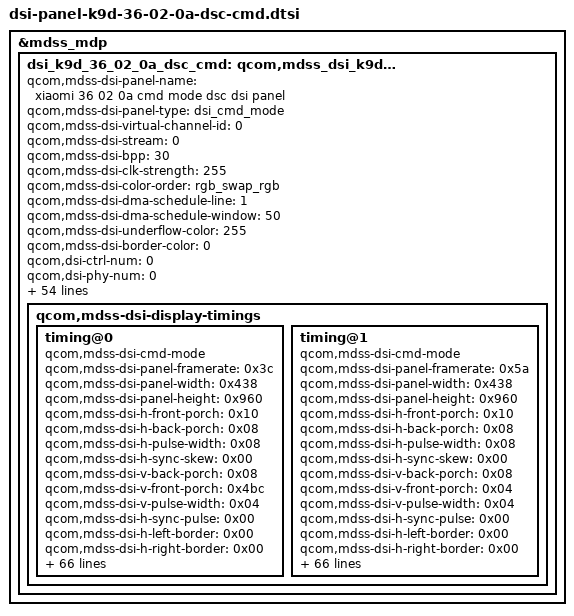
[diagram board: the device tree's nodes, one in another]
&mdss_mdp {
	dsi_k9d_36_02_0a_dsc_cmd: qcom,mdss_dsi_k9d_36_02_0a_dsc_cmd {
		qcom,mdss-dsi-panel-name = "xiaomi 36 02 0a cmd mode dsc dsi panel";
		qcom,mdss-dsi-panel-type = "dsi_cmd_mode";
		qcom,mdss-dsi-virtual-channel-id = <0>;
		qcom,mdss-dsi-stream = <0>;
		qcom,mdss-dsi-bpp = <30>;
		qcom,mdss-dsi-clk-strength = <255>;
		qcom,mdss-dsi-color-order = "rgb_swap_rgb";
		qcom,mdss-dsi-dma-schedule-line = <1>;
		qcom,mdss-dsi-dma-schedule-window = <50>;
		qcom,mdss-dsi-underflow-color = <255>;
		qcom,mdss-dsi-border-color = <0>;

		qcom,dsi-ctrl-num = <0>;
		qcom,dsi-phy-num = <0>;

		qcom,mdss-dsi-traffic-mode = "burst_mode";
		qcom,mdss-dsi-lane-map = "lane_map_0123";
		qcom,mdss-dsi-bllp-eof-power-mode;
		qcom,mdss-dsi-bllp-power-mode;
		qcom,mdss-dsi-lane-0-state;
		qcom,mdss-dsi-lane-1-state;
		qcom,mdss-dsi-lane-2-state;
		qcom,mdss-dsi-lane-3-state;
		qcom,mdss-dsi-dma-trigger = "trigger_sw";
		qcom,mdss-dsi-mdp-trigger = "none";
		qcom,mdss-dsi-reset-sequence =  <1 11>, <0 1>, <1 11>;
		qcom,mdss-factory-brightness-max-level = <2047>;
		qcom,mdss-pan-physical-height-dimension = <1517>;
		qcom,mdss-pan-physical-width-dimension = <683>;
		qcom,mdss-dsi-te-pin-select = <1>;
		qcom,mdss-dsi-wr-mem-start = <0x2c>;
		qcom,mdss-dsi-wr-mem-continue = <0x3c>;
		qcom,mdss-dsi-te-dcs-command = <1>;
		qcom,mdss-dsi-te-check-enable;
		qcom,mdss-dsi-te-using-te-pin;
		qcom,mdss-dsi-tx-eot-append;
		qcom,mdss-dsi-lp11-init;

		qcom,mdss-dsi-bl-inverted-dbv;
		qcom,bl-update-flag = "delay_until_first_frame";
		qcom,mdss-dsi-panel-blackness-level = <3230>;
		qcom,mdss-dsi-panel-hdr-color-primaries = <0x38a4 0x3c8c 0x7d00 0x4268 0x3c8c 0x7530 0x1f40 0xbb8>;
		qcom,mdss-dsi-panel-hdr-enabled;

		qcom,mdss-dsi-display-timings {
			timing@0{
				qcom,mdss-dsi-cmd-mode;
				qcom,mdss-dsi-panel-framerate = <60>;
				qcom,mdss-dsi-panel-width = <1080>;
				qcom,mdss-dsi-panel-height = <2400>;
				qcom,mdss-dsi-h-front-porch = <16>;
				qcom,mdss-dsi-h-back-porch = <8>;
				qcom,mdss-dsi-h-pulse-width = <8>;
				qcom,mdss-dsi-h-sync-skew = <0>;
				qcom,mdss-dsi-v-back-porch = <8>;
				qcom,mdss-dsi-v-front-porch = <1212>;
				qcom,mdss-dsi-v-pulse-width = <4>;
				qcom,mdss-dsi-h-sync-pulse = <0>;
				qcom,mdss-dsi-h-left-border = <0>;
				qcom,mdss-dsi-h-right-border = <0>;
				qcom,mdss-dsi-v-top-border = <0>;
				qcom,mdss-dsi-v-bottom-border = <0>;
				qcom,mdss-dsi-panel-clockrate = <682000000>;
				qcom,mdss-dsi-panel-jitter = <0x5 0x1>;
				qcom,mdss-mdp-transfer-time-us = <9500>;
				qcom,mdss-dsi-on-command = [
					/* Command Mode */
					39 00 00 00 00 00 06 F0 55 AA 52 08 00
					39 01 00 00 00 00 03 C0 52 F3
					/* ESD/MIPI Error Flag, Low when Error Happen */
					39 00 00 00 00 00 06 F0 55 AA 52 08 00
					39 00 00 00 00 00 05 BE 0E 0B 14 13
					15 00 00 00 00 00 02 6F 05
					15 01 00 00 00 00 02 BE 8A
					/* Round Corner OFF */
					39 00 00 00 00 00 06 F0 55 AA 52 08 07
					39 01 00 00 00 00 03 C0 00 02
					/* VESA ON */
					39 00 00 00 00 00 06 F0 55 AA 52 08 01	// Set page 1
					39 00 00 00 00 00 04 D1 07 00 04
					39 00 00 00 00 00 05 B3 12 12 22 22
					39 00 00 00 00 00 05 B4 12 12 22 22
					15 01 00 00 00 00 02 90 01
					/* Choose VESA Edition */
					39 00 00 00 00 00 13 91
						AB 28 00 0C C2 00 03 1C 01 7E
						00 0F 08 BB 04 3D 10 F0	// DSC Setting
					15 00 00 00 00 00 02 03 01
					39 00 00 00 00 00 05 51 00 00 00 00	// Normal Mode
					15 00 00 00 00 00 02 53 20
					15 00 00 00 00 00 02 35 00	// TE ON
					39 00 00 00 00 00 05 2A 00 00 04 37
					39 00 00 00 00 00 05 2B 00 00 09 5F
					15 01 00 00 00 00 02 2F 02	// 60Hz
					/* OSC=109.2MHz */
					39 00 00 00 00 00 05 FF AA 55 A5 81
					15 00 00 00 00 00 02 6F 0F
					39 01 00 00 00 00 03 FD 01 5A
					/* Demura Gain */
					39 00 00 00 00 00 05 FF AA 55 A5 80
					39 00 00 00 00 00 04 C0 76 F3 C1
					39 00 00 00 00 00 06 F0 55 AA 52 08 04
					15 00 00 00 00 00 02 C2 14
					15 00 00 00 00 00 02 B1 02
					15 00 00 00 00 00 02 B2 40
					15 00 00 00 00 00 02 6F 04
					39 00 00 00 00 00 04 B2 09 E4 00
					15 00 00 00 00 00 02 6F 0A
					39 00 00 00 00 00 04 B2 09 E3 40
					15 00 00 00 00 00 02 CB A4
					39 01 00 00 00 00 05 D0 00 80 00 20
					/* AOD Demura */
					15 00 00 00 00 00 02 B0 01
					39 00 00 00 00 00 06 F0 55 AA 52 08 00
					15 00 00 00 00 00 02 6F 01
					15 01 00 00 00 00 02 C0 B3
					/* AOD Demura End */
					39 00 00 00 00 00 06 F0 55 AA 52 08 04
					15 00 00 00 00 00 02 6F 04
					15 01 00 00 00 00 02 D0 01
					39 00 00 00 00 00 06 F0 55 AA 52 08 00
					15 00 00 00 00 00 02 6F 08
					15 00 00 00 00 00 02 C0 55
					15 01 00 00 00 00 02 8B 10
					39 00 00 00 00 00 06 F0 55 AA 52 08 04
					15 00 00 00 00 00 02 6F 01
					39 01 00 00 00 00 10 CB
						10 20 30 40 80 00 08 00 F6 01
						C2 04 CC 07 FF
					/* 90Hz Gain */
					39 01 00 00 00 00 4C D2
						E0 50 36 2C 27 B0 56 48 34 2E
						A0 60 51 40 32 90 69 59 47 40
						90 73 60 4C 40 E0 50 36 2C 27
						B0 56 48 34 2E A0 60 51 40 32
						90 69 59 47 40 90 73 60 4C 40
						E0 50 36 2C 27 B0 56 48 34 2E
						A0 60 51 40 32 90 69 59 47 40
						90 73 60 4C 40
					/* 60Hz Gain */
					39 01 00 00 00 00 4C D4
						C0 A0 90 90 90 36 39 40 50 60
						25 2C 38 46 5A 24 2B 35 44 48
						13 2A 32 42 42 C0 A0 90 90 90
						36 39 40 50 60 25 2C 38 46 5A
						24 2B 35 44 48 13 2A 32 42 42
						C0 A0 90 90 90 36 39 40 50 60
						25 2C 38 46 5A 24 2B 35 44 48
						13 2A 32 42 42
					/* Demura DC */
					39 01 00 00 00 00 4C D9
						40 40 40 40 40 40 40 40 40 40
						40 40 40 40 40 40 40 40 40 40
						40 40 40 40 40 40 40 40 40 40
						40 40 40 40 40 40 40 40 40 40
						40 40 40 40 40 40 40 40 40 40
						40 40 40 40 40 40 40 40 40 40
						40 40 40 40 40 40 40 40 40 40
						40 40 40 40 40
					/* FCON code */
					39 00 00 00 00 00 06 F0 55 AA 52 08 00
					/* FCON = 1 (90hz) */
					39 00 00 00 00 00 09 BA 01 E9 00 10 00 30 00 01
					/* FCON = 2 (60hz) */
					15 00 00 00 00 00 02 6F 08
					39 00 00 00 00 00 09 BA 01 E9 00 10 04 D0 00 01	// PWM 60&90Hz
					/* FCON = 3 (DC=60hz) */
					15 00 00 00 00 00 02 6F 10
					39 00 00 00 00 00 09 BA 01 E9 00 10 04 D0 00 01
					39 00 00 00 00 00 03 B2 50 63
					15 00 00 00 00 00 02 6F 05
					39 00 00 00 00 00 03 B2 30 30	// Dimming speed: 48 DBV/Frame
					15 00 00 00 00 00 02 6F 0F
					39 00 00 00 00 00 03 B2 20 50
					/* EM_DT_0_HFR1 ~EM_DT_0_HFR18 (60hz) */
					15 00 00 00 00 00 02 6F 2C
					39 00 00 00 00 00 27 B3
						0E 40 0D F5 0C D2 0C D2 0C 3C
						0C 3C 0A 51 0A 51 06 44 06 44
						00 6A 00 6A 00 6A 00 6A 00 6A
						00 6A 00 6A 00 6A 00 6A
					/* EM_DT_0~EM_DT_18 (90hz) */
					39 01 00 00 00 00 27 B4
						09 A0 09 6E 08 A9 08 A9 08 44
						08 44 06 F8 06 F8 04 3C 04 3C
						00 48 00 48 00 48 00 48 00 48
						00 48 00 48 00 48 00 48
					/* Sleep Out */
					05 01 00 00 78 00 02 11 00
					/* Display On */
					05 01 00 00 10 00 02 29 00];
				qcom,mdss-dsi-off-command = [
					05 01 00 00 00 00 02 28 00
					05 01 00 00 78 00 02 10 00];
				qcom,mdss-dsi-on-command-state = "dsi_lp_mode";
				qcom,mdss-dsi-off-command-state = "dsi_lp_mode";

				qcom,mdss-dsi-timing-switch-command = [
					15 01 00 00 00 00 02 2F 02];
				qcom,mdss-dsi-timing-switch-command-state = "dsi_lp_mode";

				qcom,mdss-dsi-nolp-command = [
					15 00 00 00 00 00 02 65 00
					05 00 00 00 00 00 01 38
					05 00 00 00 00 00 01 2C
					15 01 00 00 00 00 02 2F 02];
				qcom,mdss-dsi-nolp-command-state = "dsi_lp_mode";

				qcom,compression-mode = "dsc";
				qcom,mdss-dsc-version = <0x11>;
				qcom,mdss-dsc-scr-version = <0x0>;
				qcom,mdss-dsc-slice-height = <12>;
				qcom,mdss-dsc-slice-width = <1080>;
				qcom,mdss-dsc-slice-per-pkt = <1>;
				qcom,mdss-dsc-bit-per-component = <10>;
				qcom,mdss-dsc-bit-per-pixel = <8>;
				qcom,mdss-dsc-block-prediction-enable;
			};

			timing@1{
				qcom,mdss-dsi-cmd-mode;
				qcom,mdss-dsi-panel-framerate = <90>;
				qcom,mdss-dsi-panel-width = <1080>;
				qcom,mdss-dsi-panel-height = <2400>;
				qcom,mdss-dsi-h-front-porch = <16>;
				qcom,mdss-dsi-h-back-porch = <8>;
				qcom,mdss-dsi-h-pulse-width = <8>;
				qcom,mdss-dsi-h-sync-skew = <0>;
				qcom,mdss-dsi-v-back-porch = <8>;
				qcom,mdss-dsi-v-front-porch = <4>;
				qcom,mdss-dsi-v-pulse-width = <4>;
				qcom,mdss-dsi-h-sync-pulse = <0>;
				qcom,mdss-dsi-h-left-border = <0>;
				qcom,mdss-dsi-h-right-border = <0>;
				qcom,mdss-dsi-v-top-border = <0>;
				qcom,mdss-dsi-v-bottom-border = <0>;
				qcom,mdss-dsi-panel-clockrate = <682000000>;
				qcom,mdss-dsi-panel-jitter = <0x5 0x1>;
				qcom,mdss-mdp-transfer-time-us = <9500>;
				qcom,mdss-dsi-on-command = [
					/* Command Mode */
					39 00 00 00 00 00 06 F0 55 AA 52 08 00
					39 01 00 00 00 00 03 C0 52 F3
					/* ESD/MIPI Error Flag, Low when Error Happen */
					39 00 00 00 00 00 06 F0 55 AA 52 08 00
					39 00 00 00 00 00 05 BE 0E 0B 14 13
					15 00 00 00 00 00 02 6F 05
					15 01 00 00 00 00 02 BE 8A
					/* Round Corner OFF */
					39 00 00 00 00 00 06 F0 55 AA 52 08 07
					39 01 00 00 00 00 03 C0 00 02
					/* VESA ON */
					39 00 00 00 00 00 06 F0 55 AA 52 08 01	// Set page 1
					39 00 00 00 00 00 04 D1 07 00 04
					39 00 00 00 00 00 05 B3 12 12 22 22
					39 00 00 00 00 00 05 B4 12 12 22 22
					15 01 00 00 00 00 02 90 01
					/* Choose VESA Edition */
					39 00 00 00 00 00 13 91
						AB 28 00 0C C2 00 03 1C 01 7E
						00 0F 08 BB 04 3D 10 F0	// DSC Setting
					15 00 00 00 00 00 02 03 01
					39 00 00 00 00 00 05 51 00 00 00 00	// Normal Mode
					15 00 00 00 00 00 02 53 20
					15 00 00 00 00 00 02 35 00	// TE ON
					39 00 00 00 00 00 05 2A 00 00 04 37
					39 00 00 00 00 00 05 2B 00 00 09 5F
					15 01 00 00 00 00 02 2F 01	// 90Hz
					/* OSC=109.2MHz */
					39 00 00 00 00 00 05 FF AA 55 A5 81
					15 00 00 00 00 00 02 6F 0F
					39 01 00 00 00 00 03 FD 01 5A
					/* Demura Gain */
					39 00 00 00 00 00 05 FF AA 55 A5 80
					39 01 00 00 00 00 04 C0 76 F3 C1
					39 00 00 00 00 00 06 F0 55 AA 52 08 04
					15 00 00 00 00 00 02 C2 14
					15 00 00 00 00 00 02 B1 02
					15 00 00 00 00 00 02 B2 40
					15 00 00 00 00 00 02 6F 04
					39 00 00 00 00 00 04 B2 09 E4 00
					15 00 00 00 00 00 02 6F 0A
					39 00 00 00 00 00 04 B2 09 E3 40
					15 00 00 00 00 00 02 CB A4
					39 01 00 00 00 00 05 D0 00 80 00 20
					/* AOD Demura */
					15 00 00 00 00 00 02 B0 01
					39 00 00 00 00 00 06 F0 55 AA 52 08 00
					15 00 00 00 00 00 02 6F 01
					15 01 00 00 00 00 02 C0 B3
					/* AOD Demura End */
					39 00 00 00 00 00 06 F0 55 AA 52 08 04
					15 00 00 00 00 00 02 6F 04
					15 01 00 00 00 00 02 D0 01
					39 00 00 00 00 00 06 F0 55 AA 52 08 00
					15 00 00 00 00 00 02 6F 08
					15 00 00 00 00 00 02 C0 55
					15 01 00 00 00 00 02 8B 10
					39 00 00 00 00 00 06 F0 55 AA 52 08 04
					15 00 00 00 00 00 02 6F 01
					39 01 00 00 00 00 10 CB
						10 20 30 40 80 00 08 00 F6 01
						C2 04 CC 07 FF
					/* 90Hz Gain */
					39 01 00 00 00 00 4C D2
						E0 50 36 2C 27 B0 56 48 34 2E
						A0 60 51 40 32 90 69 59 47 40
						90 73 60 4C 40 E0 50 36 2C 27
						B0 56 48 34 2E A0 60 51 40 32
						90 69 59 47 40 90 73 60 4C 40
						E0 50 36 2C 27 B0 56 48 34 2E
						A0 60 51 40 32 90 69 59 47 40
						90 73 60 4C 40
					/* 60Hz Gain */
					39 01 00 00 00 00 4C D4
						C0 A0 90 90 90 36 39 40 50 60
						25 2C 38 46 5A 24 2B 35 44 48
						13 2A 32 42 42 C0 A0 90 90 90
						36 39 40 50 60 25 2C 38 46 5A
						24 2B 35 44 48 13 2A 32 42 42
						C0 A0 90 90 90 36 39 40 50 60
						25 2C 38 46 5A 24 2B 35 44 48
						13 2A 32 42 42
					/* Demura DC */
					39 01 00 00 00 00 4C D9
						40 40 40 40 40 40 40 40 40 40
						40 40 40 40 40 40 40 40 40 40
						40 40 40 40 40 40 40 40 40 40
						40 40 40 40 40 40 40 40 40 40
						40 40 40 40 40 40 40 40 40 40
						40 40 40 40 40 40 40 40 40 40
						40 40 40 40 40 40 40 40 40 40
						40 40 40 40 40
					/* FCON code */
					39 00 00 00 00 00 06 F0 55 AA 52 08 00
					/* FCON = 1 (90hz) */
					39 00 00 00 00 00 09 BA 01 E9 00 10 00 30 00 01
					/* FCON = 2 (60hz) */
					15 00 00 00 00 00 02 6F 08
					39 00 00 00 00 00 09 BA 01 E9 00 10 04 D0 00 01	// PWM 60&90Hz
					/* FCON = 3 (DC=60hz) */
					15 00 00 00 00 00 02 6F 10
					39 00 00 00 00 00 09 BA 01 E9 00 10 04 D0 00 01
					39 00 00 00 00 00 03 B2 50 63
					15 00 00 00 00 00 02 6F 05
					39 00 00 00 00 00 03 B2 20 20	// Dimming speed: 32 DBV/Frame
					15 00 00 00 00 00 02 6F 0F
					39 00 00 00 00 00 03 B2 20 50
					/* EM_DT_0_HFR1 ~EM_DT_0_HFR18 (60hz) */
					15 00 00 00 00 00 02 6F 2C
					39 00 00 00 00 00 27 B3
						0E 40 0D F5 0C D2 0C D2 0C 3C
						0C 3C 0A 51 0A 51 06 44 06 44
						00 6A 00 6A 00 6A 00 6A 00 6A
						00 6A 00 6A 00 6A 00 6A
					/* EM_DT_0~EM_DT_18 (90hz) */
					39 01 00 00 00 00 27 B4
						09 A0 09 6E 08 A9 08 A9 08 44
						08 44 06 F8 06 F8 04 3C 04 3C
						00 48 00 48 00 48 00 48 00 48
						00 48 00 48 00 48 00 48
					/* Sleep Out */
					05 01 00 00 8C 00 02 11 00
					/* Display On */
					05 01 00 00 10 00 02 29 00];
				qcom,mdss-dsi-off-command = [
					05 01 00 00 00 00 02 28 00
					05 01 00 00 78 00 02 10 00];
				qcom,mdss-dsi-on-command-state = "dsi_lp_mode";
				qcom,mdss-dsi-off-command-state = "dsi_lp_mode";

				qcom,mdss-dsi-timing-switch-command = [
					15 01 00 00 00 00 02 2F 01];
				qcom,mdss-dsi-timing-switch-command-state = "dsi_lp_mode";

				qcom,mdss-dsi-nolp-command = [
					15 00 00 00 00 00 02 65 00
					05 00 00 00 00 00 01 38
					05 00 00 00 00 00 01 2C
					15 01 00 00 00 00 02 2F 01];
				qcom,mdss-dsi-nolp-command-state = "dsi_lp_mode";

				qcom,compression-mode = "dsc";
				qcom,mdss-dsc-version = <0x11>;
				qcom,mdss-dsc-scr-version = <0x0>;
				qcom,mdss-dsc-slice-height = <12>;
				qcom,mdss-dsc-slice-width = <1080>;
				qcom,mdss-dsc-slice-per-pkt = <1>;
				qcom,mdss-dsc-bit-per-component = <10>;
				qcom,mdss-dsc-bit-per-pixel = <8>;
				qcom,mdss-dsc-block-prediction-enable;
			};
		};
	};
};

&dsi_k9d_36_02_0a_dsc_cmd {
	mi,panel-id = <0x4b3944 0x360200>;
	mi,fp-display-on-optimize-flag;
	mi,hbm-51-ctl-flag;
	mi,hbm-off-51-index = <1>;
	mi,hbm-on-51-index = <1>;
	mi,max-brightness-clone = <4095>;
	mi,hbm-bl-min-level = <1>;
	mi,hbm-bl-max-level = <2047>;
	mi,panel-on-dimming-delay = <120>;
	mi,thermal-dimming-flag;
	mi,timming-switch-wait-for-te-flag;

	/* IRQF_ONESHOT | IRQF_TRIGGER_FALLING */
	mi,esd-err-irq-gpio = <&tlmm 3 0x2002>;

	qcom,esd-check-enabled;
	qcom,esd-aod-check-enabled;
	qcom,mdss-dsi-panel-status-check-mode = "reg_read";
	qcom,mdss-dsi-panel-status-offset-command = [
		39 01 00 00 00 00 05 FF AA 55 A5 81
		15 01 00 00 00 00 02 6F 0F];
	qcom,mdss-dsi-panel-status-command = [06 01 00 00 00 00 01 FA];
	qcom,mdss-dsi-panel-status-command-state = "dsi_lp_mode";
	qcom,mdss-dsi-panel-status-offset-command-state = "dsi_lp_mode";
	qcom,mdss-dsi-panel-status-value = <0x00>;
	qcom,mdss-dsi-panel-status-read-length = <1>;

	qcom,mdss-dsi-display-timings {
		timing@0 {
			mi,mdss-dsc-panel-id = <0x4b3944 0x360200>;
			mi,mdss-dsi-dimmingoff-command = [15 01 00 00 00 00 02 53 20];
			mi,mdss-dsi-dimmingoff-command-state = "dsi_hs_mode";
			mi,mdss-dsi-dimmingon-command = [15 01 00 00 00 00 02 53 28];
			mi,mdss-dsi-dimmingon-command-state = "dsi_hs_mode";
			mi,mdss-dsi-doze-hbm-command = [15 01 00 00 00 00 02 2f 01 39 01 00 00 00 00 05 51 00 00 03 ff 05 01 00 00 14 00 01 39 15 01 00 00 00 00 02 65 01];
			mi,mdss-dsi-doze-hbm-command-state = "dsi_lp_mode";
			mi,mdss-dsi-doze-lbm-command = [15 01 00 00 00 00 02 2f 01 39 01 00 00 00 00 05 51 00 00 01 ff 05 01 00 00 14 00 01 39 15 01 00 00 00 00 02 65 01];
			mi,mdss-dsi-doze-lbm-command-state = "dsi_lp_mode";
			mi,mdss-dsi-flat-mode-off-command = [39 01 00 00 00 00 06 f0 55 aa 52 08 08 15 01 00 00 00 00 02 b9 00];
			mi,mdss-dsi-flat-mode-off-command-state = "dsi_lp_mode";
			mi,mdss-dsi-flat-mode-on-command = [39 01 00 00 00 00 06 f0 55 aa 52 08 08 15 01 00 00 00 00 02 b9 01];
			mi,mdss-dsi-flat-mode-on-command-state = "dsi_lp_mode";
			mi,mdss-dsi-hbm-off-command = [15 01 00 00 00 00 02 53 28 39 01 00 00 00 00 05 51 07 ff 00 00];
			mi,mdss-dsi-hbm-off-command-state = "dsi_lp_mode";
			mi,mdss-dsi-hbm-on-command = [15 01 00 00 00 00 02 53 28 39 01 00 00 00 00 05 51 0f ff 00 00];
			mi,mdss-dsi-hbm-on-command-state = "dsi_lp_mode";
			mi,mdss-dsi-pre-doze-to-off-command = [39 00 00 00 00 00 06 f0 55 aa 52 08 01 39 01 00 00 00 00 02 ce 0c];
			mi,mdss-dsi-pre-doze-to-off-command-state = "dsi_lp_mode";
			qcom,compression-mode = "dsc";
			qcom,default-topology-index = <0x00>;
			qcom,display-topology = <0x01 0x01 0x01>;
			qcom,mdss-dsc-bit-per-component = <0x0a>;
			qcom,mdss-dsc-bit-per-pixel = <0x08>;
			qcom,mdss-dsc-block-prediction-enable;
			qcom,mdss-dsc-scr-version = <0x00>;
			qcom,mdss-dsc-slice-height = <0x0c>;
			qcom,mdss-dsc-slice-per-pkt = <0x01>;
			qcom,mdss-dsc-slice-width = <0x438>;
			qcom,mdss-dsc-version = <0x11>;
			qcom,mdss-dsi-cmd-mode;
			qcom,mdss-dsi-h-back-porch = <0x08>;
			qcom,mdss-dsi-h-front-porch = <0x10>;
			qcom,mdss-dsi-h-left-border = <0x00>;
			qcom,mdss-dsi-h-pulse-width = <0x08>;
			qcom,mdss-dsi-h-right-border = <0x00>;
			qcom,mdss-dsi-h-sync-pulse = <0x00>;
			qcom,mdss-dsi-h-sync-skew = <0x00>;
			qcom,mdss-dsi-nolp-command = [15 01 00 00 00 00 02 65 00 05 01 00 00 07 00 01 38 39 01 00 00 00 00 06 f0 55 aa 52 08 01 39 01 00 00 1b 00 05 ba 10 1a 10 1a 39 01 00 00 00 00 05 ba 10 10 10 10 15 01 00 00 00 00 02 2f 02];
			qcom,mdss-dsi-nolp-command-state = "dsi_lp_mode";
			qcom,mdss-dsi-off-command = [05 01 00 00 14 00 02 28 00 05 01 00 00 50 00 02 10 00];
			qcom,mdss-dsi-off-command-state = "dsi_lp_mode";
			qcom,mdss-dsi-on-command = [39 01 00 00 00 00 06 f0 55 aa 52 08 00 39 00 00 00 00 00 09 ba 01 e6 00 10 00 30 00 01 15 00 00 00 00 00 02 b2 58 15 00 00 00 00 00 02 6f 02 39 00 00 00 00 00 03 b2 0c 0c 39 00 00 00 00 00 05 be 0e 0b 14 13 15 00 00 00 00 00 02 6f 05 15 00 00 00 00 00 02 be 8a 15 00 00 00 00 00 02 c0 66 15 00 00 00 00 00 02 6f 08 15 01 00 00 00 00 02 b5 32 39 00 00 00 00 00 06 f0 55 aa 52 08 07 39 01 00 00 00 00 03 c0 00 02 39 01 00 00 00 00 06 f0 55 aa 52 08 01 39 00 00 00 00 00 02 6f 01 39 00 00 00 00 00 04 d2 00 00 11 39 00 00 00 00 00 02 6f 06 39 00 00 00 00 00 02 d2 05 39 00 00 00 00 00 02 6f 0f 39 00 00 00 00 00 02 d2 00 39 00 00 00 00 00 02 6f 09 39 00 00 00 00 00 03 d2 00 00 39 00 00 00 00 00 02 ce 00 39 00 00 00 00 00 05 ff aa 55 a5 80 39 00 00 00 00 00 02 6f 61 39 00 00 00 00 00 02 f3 80 39 00 00 00 00 00 06 f0 55 aa 52 08 00 39 00 00 00 00 00 02 c0 46 39 00 00 00 00 00 03 be 0e 0b 39 00 00 00 00 00 02 6f 05 39 00 00 00 00 00 02 be 88 39 00 00 00 00 00 02 6f 08 39 00 00 00 00 00 02 b5 32 39 00 00 00 00 00 02 6f 0b 39 00 00 00 00 00 04 b5 33 23 2b 39 00 00 00 00 00 06 f0 55 aa 52 08 01 39 00 00 00 00 00 04 d1 07 00 04 39 00 00 00 00 00 05 3b 00 10 00 30 39 00 00 00 00 00 02 d9 c8 15 01 00 00 00 00 02 90 01 39 00 00 00 00 00 13 91 ab 28 00 0c c2 00 03 1c 01 7e 00 0f 08 bb 04 3d 10 f0 15 00 00 00 00 00 02 03 01 39 00 00 00 00 00 05 51 00 00 00 00 15 00 00 00 00 00 02 53 20 15 00 00 00 00 00 02 35 00 39 00 00 00 00 00 05 2a 00 00 04 37 39 00 00 00 00 00 05 2b 00 00 09 5f 15 01 00 00 00 00 02 2f 02 39 00 00 00 00 00 05 ff aa 55 a5 81 15 00 00 00 00 00 02 6f 0f 39 00 00 00 00 00 03 fd 01 5a 15 00 00 00 00 00 02 6f 04 15 00 00 00 00 00 02 fd 5f 15 00 00 00 00 00 02 6f 1a 15 00 00 00 00 00 02 fd 5f 05 01 00 00 00 00 01 2c 39 00 00 00 00 00 06 f0 55 aa 52 08 00 39 00 00 00 00 00 05 ca 12 00 92 02 15 00 00 00 00 00 02 6f 02 39 00 00 00 00 00 03 ec 80 10 39 00 00 00 00 00 06 f0 55 aa 52 08 01 39 00 00 00 00 00 03 cd 05 31 15 00 00 00 00 00 02 6f 10 15 00 00 00 00 00 02 d8 0c 39 00 00 00 00 00 06 f0 55 aa 52 08 05 39 00 00 00 00 00 03 b3 86 80 39 00 00 00 00 00 03 b5 85 81 39 00 00 00 00 00 05 b7 85 00 00 81 39 00 00 00 00 00 05 b8 05 00 00 81 39 00 00 00 00 00 03 ec 0d 11 15 00 00 00 00 00 02 6f 02 39 01 00 00 00 00 13 ec 00 00 00 00 00 00 00 00 00 00 00 00 00 00 00 00 00 00 39 00 00 00 00 00 06 f0 55 aa 52 08 01 15 00 00 00 00 00 02 6f 01 39 00 00 00 00 00 04 d2 01 28 33 15 00 00 00 00 00 02 6f 06 15 00 00 00 00 00 02 d2 00 15 00 00 00 00 00 02 6f 0f 15 00 00 00 00 00 02 d2 00 39 00 00 00 00 00 08 c3 94 01 97 d0 22 02 00 15 00 00 00 00 00 02 6f 09 15 01 00 00 00 00 02 d2 00 05 01 00 00 32 00 02 11 00 05 01 00 00 10 00 02 29 00];
			qcom,mdss-dsi-on-command-state = "dsi_lp_mode";
			qcom,mdss-dsi-panel-clockrate = <0x28a67e80>;
			qcom,mdss-dsi-panel-framerate = <0x3c>;
			qcom,mdss-dsi-panel-height = <0x960>;
			qcom,mdss-dsi-panel-jitter = <0x05 0x01>;
			qcom,mdss-dsi-panel-phy-timings = [00 18 06 06 21 20 06 06 04 02 04 00 15 16];
			qcom,mdss-dsi-panel-width = <0x438>;
			qcom,mdss-dsi-timing-switch-command = [15 01 00 00 00 00 02 2f 02];
			qcom,mdss-dsi-timing-switch-command-state = "dsi_lp_mode";
			qcom,mdss-dsi-v-back-porch = <0x08>;
			qcom,mdss-dsi-v-bottom-border = <0x00>;
			qcom,mdss-dsi-v-front-porch = <0x4bc>;
			qcom,mdss-dsi-v-pulse-width = <0x04>;
			qcom,mdss-dsi-v-top-border = <0x00>;
			qcom,mdss-mdp-transfer-time-us = <0x3d54>;
		};

		timing@1{
					mi,mdss-dsc-panel-id = <0x4b3944 0x360200>;
			mi,mdss-dsi-dimmingoff-command = [15 01 00 00 00 00 02 53 20];
			mi,mdss-dsi-dimmingoff-command-state = "dsi_hs_mode";
			mi,mdss-dsi-dimmingon-command = [15 01 00 00 00 00 02 53 28];
			mi,mdss-dsi-dimmingon-command-state = "dsi_hs_mode";
			mi,mdss-dsi-doze-hbm-command = [15 01 00 00 00 00 02 2f 01 39 01 00 00 00 00 05 51 00 00 03 ff 05 01 00 00 14 00 01 39 15 01 00 00 00 00 02 65 01];
			mi,mdss-dsi-doze-hbm-command-state = "dsi_lp_mode";
			mi,mdss-dsi-doze-lbm-command = [15 01 00 00 00 00 02 2f 01 39 01 00 00 00 00 05 51 00 00 01 ff 05 01 00 00 14 00 01 39 15 01 00 00 00 00 02 65 01];
			mi,mdss-dsi-doze-lbm-command-state = "dsi_lp_mode";
			mi,mdss-dsi-flat-mode-off-command = [39 01 00 00 00 00 06 f0 55 aa 52 08 08 15 01 00 00 00 00 02 b9 00];
			mi,mdss-dsi-flat-mode-off-command-state = "dsi_lp_mode";
			mi,mdss-dsi-flat-mode-on-command = [39 01 00 00 00 00 06 f0 55 aa 52 08 08 15 01 00 00 00 00 02 b9 01];
			mi,mdss-dsi-flat-mode-on-command-state = "dsi_lp_mode";
			mi,mdss-dsi-hbm-off-command = [15 01 00 00 00 00 02 53 28 39 01 00 00 00 00 05 51 07 ff 00 00];
			mi,mdss-dsi-hbm-off-command-state = "dsi_lp_mode";
			mi,mdss-dsi-hbm-on-command = [15 01 00 00 00 00 02 53 28 39 01 00 00 00 00 05 51 0f ff 00 00];
			mi,mdss-dsi-hbm-on-command-state = "dsi_lp_mode";
			mi,mdss-dsi-pre-doze-to-off-command = [39 00 00 00 00 00 06 f0 55 aa 52 08 01 39 01 00 00 00 00 02 ce 0c];
			mi,mdss-dsi-pre-doze-to-off-command-state = "dsi_lp_mode";
			qcom,compression-mode = "dsc";
			qcom,default-topology-index = <0x00>;
			qcom,display-topology = <0x01 0x01 0x01>;
			qcom,mdss-dsc-bit-per-component = <0x0a>;
			qcom,mdss-dsc-bit-per-pixel = <0x08>;
			qcom,mdss-dsc-block-prediction-enable;
			qcom,mdss-dsc-scr-version = <0x00>;
			qcom,mdss-dsc-slice-height = <0x0c>;
			qcom,mdss-dsc-slice-per-pkt = <0x01>;
			qcom,mdss-dsc-slice-width = <0x438>;
			qcom,mdss-dsc-version = <0x11>;
			qcom,mdss-dsi-cmd-mode;
			qcom,mdss-dsi-h-back-porch = <0x08>;
			qcom,mdss-dsi-h-front-porch = <0x10>;
			qcom,mdss-dsi-h-left-border = <0x00>;
			qcom,mdss-dsi-h-pulse-width = <0x08>;
			qcom,mdss-dsi-h-right-border = <0x00>;
			qcom,mdss-dsi-h-sync-pulse = <0x00>;
			qcom,mdss-dsi-h-sync-skew = <0x00>;
			qcom,mdss-dsi-nolp-command = [15 01 00 00 00 00 02 65 00 05 01 00 00 07 00 01 38 39 00 00 00 00 00 06 f0 55 aa 52 08 01 39 01 00 00 1b 00 05 ba 10 1a 10 1a 39 01 00 00 00 00 05 ba 10 10 10 10 15 01 00 00 00 00 02 2f 01];
			qcom,mdss-dsi-nolp-command-state = "dsi_lp_mode";
			qcom,mdss-dsi-off-command = [05 01 00 00 14 00 02 28 00 05 01 00 00 50 00 02 10 00];
			qcom,mdss-dsi-off-command-state = "dsi_lp_mode";
			qcom,mdss-dsi-on-command = [39 01 00 00 00 00 06 f0 55 aa 52 08 00 39 00 00 00 00 00 09 ba 01 e6 00 10 00 30 00 01 15 00 00 00 00 00 02 b2 58 15 00 00 00 00 00 02 6f 02 39 00 00 00 00 00 03 b2 12 12 39 00 00 00 00 00 05 be 0e 0b 14 13 15 00 00 00 00 00 02 6f 05 15 00 00 00 00 00 02 be 8a 15 00 00 00 00 00 02 c0 66 15 00 00 00 00 00 02 6f 08 15 00 00 00 00 00 02 b5 32 39 00 00 00 00 00 06 f0 55 aa 52 08 07 39 01 00 00 00 00 03 c0 00 02 39 01 00 00 00 00 06 f0 55 aa 52 08 01 39 00 00 00 00 00 02 6f 01 39 00 00 00 00 00 04 d2 00 00 11 39 00 00 00 00 00 02 6f 06 39 00 00 00 00 00 02 d2 05 39 00 00 00 00 00 02 6f 0f 39 00 00 00 00 00 02 d2 00 39 00 00 00 00 00 02 6f 09 39 00 00 00 00 00 03 d2 00 00 39 00 00 00 00 00 02 ce 00 39 00 00 00 00 00 05 ff aa 55 a5 80 39 00 00 00 00 00 02 6f 61 39 00 00 00 00 00 02 f3 80 39 00 00 00 00 00 06 f0 55 aa 52 08 00 39 00 00 00 00 00 02 c0 46 39 00 00 00 00 00 03 be 0e 0b 39 00 00 00 00 00 02 6f 05 39 00 00 00 00 00 02 be 88 39 00 00 00 00 00 02 6f 08 39 00 00 00 00 00 02 b5 32 39 00 00 00 00 00 02 6f 0b 39 00 00 00 00 00 04 b5 33 23 2b 39 00 00 00 00 00 06 f0 55 aa 52 08 01 39 00 00 00 00 00 04 d1 07 00 04 39 00 00 00 00 00 05 3b 00 10 00 30 39 00 00 00 00 00 02 d9 c8 15 01 00 00 00 00 02 90 01 39 00 00 00 00 00 13 91 ab 28 00 0c c2 00 03 1c 01 7e 00 0f 08 bb 04 3d 10 f0 15 00 00 00 00 00 02 03 01 39 00 00 00 00 00 05 51 00 00 00 00 15 00 00 00 00 00 02 53 20 15 00 00 00 00 00 02 35 00 39 00 00 00 00 00 05 2a 00 00 04 37 39 00 00 00 00 00 05 2b 00 00 09 5f 15 01 00 00 00 00 02 2f 01 39 00 00 00 00 00 05 ff aa 55 a5 81 15 00 00 00 00 00 02 6f 0f 39 00 00 00 00 00 03 fd 01 5a 15 00 00 00 00 00 02 6f 04 15 00 00 00 00 00 02 fd 5f 15 00 00 00 00 00 02 6f 1a 15 00 00 00 00 00 02 fd 5f 05 01 00 00 00 00 01 2c 39 00 00 00 00 00 06 f0 55 aa 52 08 00 39 00 00 00 00 00 05 ca 12 00 92 02 15 00 00 00 00 00 02 6f 02 39 00 00 00 00 00 03 ec 80 10 39 00 00 00 00 00 06 f0 55 aa 52 08 01 39 00 00 00 00 00 03 cd 05 31 15 00 00 00 00 00 02 6f 10 15 00 00 00 00 00 02 d8 0c 39 00 00 00 00 00 06 f0 55 aa 52 08 05 39 00 00 00 00 00 03 b3 86 80 39 00 00 00 00 00 03 b5 85 81 39 00 00 00 00 00 05 b7 85 00 00 81 39 00 00 00 00 00 05 b8 05 00 00 81 39 00 00 00 00 00 03 ec 0d 11 15 00 00 00 00 00 02 6f 02 39 01 00 00 00 00 13 ec 00 00 00 00 00 00 00 00 00 00 00 00 00 00 00 00 00 00 39 00 00 00 00 00 06 f0 55 aa 52 08 01 15 00 00 00 00 00 02 6f 01 39 00 00 00 00 00 04 d2 01 28 33 15 00 00 00 00 00 02 6f 06 15 00 00 00 00 00 02 d2 00 15 00 00 00 00 00 02 6f 0f 15 00 00 00 00 00 02 d2 00 39 00 00 00 00 00 08 c3 94 01 97 d0 22 02 00 15 00 00 00 00 00 02 6f 09 15 01 00 00 00 00 02 d2 00 05 01 00 00 32 00 02 11 00 05 01 00 00 10 00 02 29 00];
			qcom,mdss-dsi-on-command-state = "dsi_lp_mode";
			qcom,mdss-dsi-panel-clockrate = <0x28a67e80>;
			qcom,mdss-dsi-panel-framerate = <0x5a>;
			qcom,mdss-dsi-panel-height = <0x960>;
			qcom,mdss-dsi-panel-jitter = <0x05 0x01>;
			qcom,mdss-dsi-panel-phy-timings = [00 18 06 06 21 20 06 06 04 02 04 00 15 16];
			qcom,mdss-dsi-panel-width = <0x438>;
			qcom,mdss-dsi-timing-switch-command = [15 01 00 00 00 00 02 2f 01];
			qcom,mdss-dsi-timing-switch-command-state = "dsi_lp_mode";
			qcom,mdss-dsi-v-back-porch = <0x08>;
			qcom,mdss-dsi-v-bottom-border = <0x00>;
			qcom,mdss-dsi-v-front-porch = <0x04>;
			qcom,mdss-dsi-v-pulse-width = <0x04>;
			qcom,mdss-dsi-v-top-border = <0x00>;
			qcom,mdss-mdp-transfer-time-us = <0x251c>;
		};
	};
};
